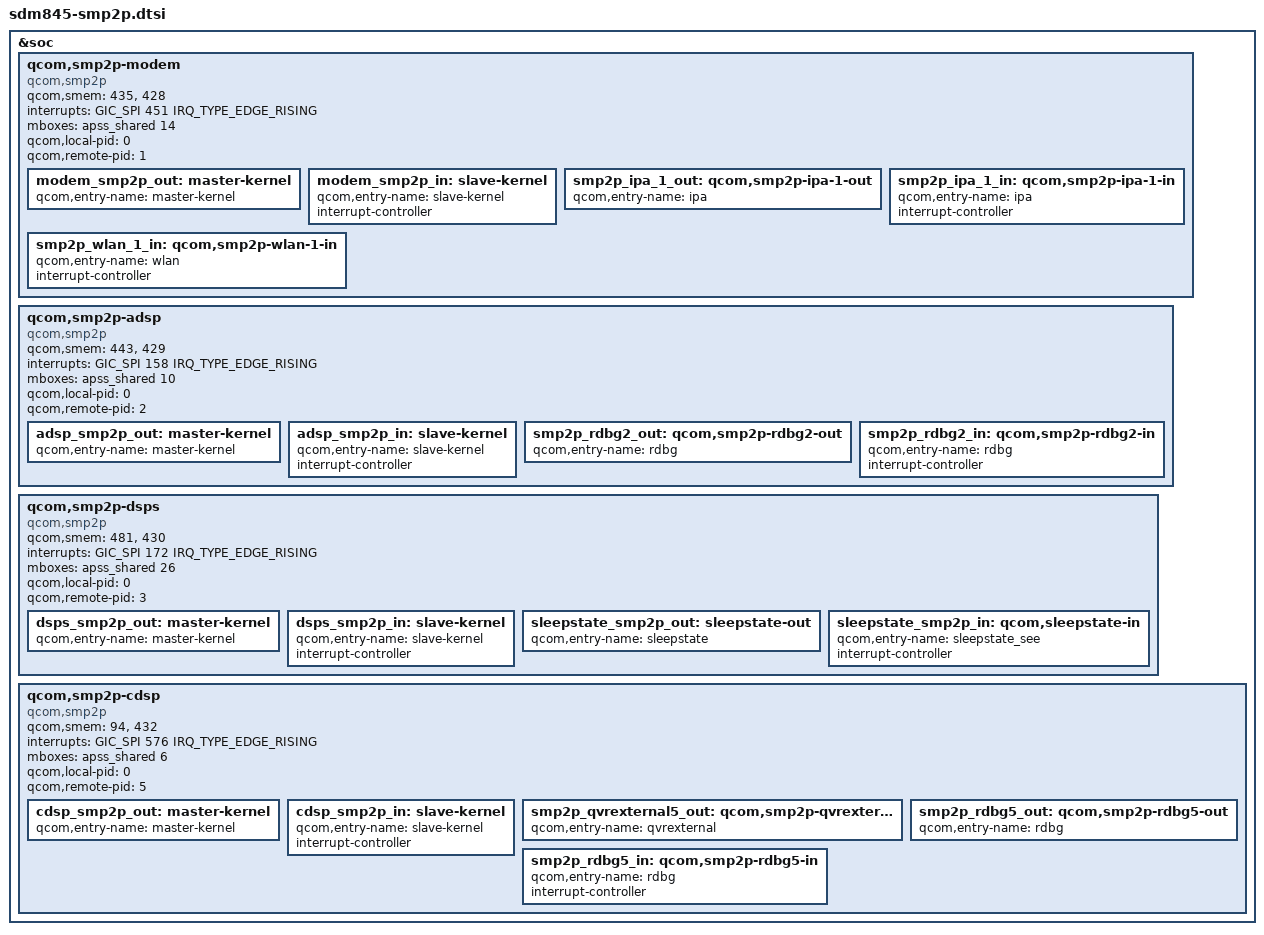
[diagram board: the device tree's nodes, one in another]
// SPDX-License-Identifier: GPL-2.0-only
/*
 * Copyright (c) 2016-2017, The Linux Foundation. All rights reserved.
 */

#include <dt-bindings/interrupt-controller/arm-gic.h>

&soc {
	qcom,smp2p-modem {
		compatible = "qcom,smp2p";
		qcom,smem = <435>, <428>;
		interrupts = <GIC_SPI 451 IRQ_TYPE_EDGE_RISING>;
		mboxes = <&apss_shared 14>;
		qcom,local-pid = <0>;
		qcom,remote-pid = <1>;

		modem_smp2p_out: master-kernel {
			qcom,entry-name = "master-kernel";
			#qcom,smem-state-cells = <1>;
		};

		modem_smp2p_in: slave-kernel {
			qcom,entry-name = "slave-kernel";
			interrupt-controller;
			#interrupt-cells = <2>;
		};

		smp2p_ipa_1_out: qcom,smp2p-ipa-1-out {
			qcom,entry-name = "ipa";
			#qcom,smem-state-cells = <1>;
		};

		/* ipa - inbound entry from mss */
		smp2p_ipa_1_in: qcom,smp2p-ipa-1-in {
			qcom,entry-name = "ipa";
			interrupt-controller;
			#interrupt-cells = <2>;
		};

		smp2p_wlan_1_in: qcom,smp2p-wlan-1-in {
			qcom,entry-name = "wlan";
			interrupt-controller;
			#interrupt-cells = <2>;
		};
	};

	qcom,smp2p-adsp {
		compatible = "qcom,smp2p";
		qcom,smem = <443>, <429>;
		interrupts = <GIC_SPI 158 IRQ_TYPE_EDGE_RISING>;
		mboxes = <&apss_shared 10>;
		qcom,local-pid = <0>;
		qcom,remote-pid = <2>;

		adsp_smp2p_out: master-kernel {
			qcom,entry-name = "master-kernel";
			#qcom,smem-state-cells = <1>;
		};

		adsp_smp2p_in: slave-kernel {
			qcom,entry-name = "slave-kernel";
			interrupt-controller;
			#interrupt-cells = <2>;
		};

		smp2p_rdbg2_out: qcom,smp2p-rdbg2-out {
			qcom,entry-name = "rdbg";
			#qcom,smem-state-cells = <1>;
		};

		smp2p_rdbg2_in: qcom,smp2p-rdbg2-in {
			qcom,entry-name = "rdbg";
			interrupt-controller;
			#interrupt-cells = <2>;
		};
	};

	qcom,smp2p-dsps {
		compatible = "qcom,smp2p";
		qcom,smem = <481>, <430>;
		interrupts = <GIC_SPI 172 IRQ_TYPE_EDGE_RISING>;
		mboxes = <&apss_shared 26>;
		qcom,local-pid = <0>;
		qcom,remote-pid = <3>;

		dsps_smp2p_out: master-kernel {
			#address-cells = <0>;
			qcom,entry-name = "master-kernel";
			#qcom,smem-state-cells = <1>;
		};

		dsps_smp2p_in: slave-kernel {
			#address-cells = <0>;
			qcom,entry-name = "slave-kernel";
			interrupt-controller;
			#interrupt-cells = <2>;
		};

		sleepstate_smp2p_out: sleepstate-out {
			#address-cells = <0>;
			qcom,entry-name = "sleepstate";
			#qcom,smem-state-cells = <1>;
		};

		sleepstate_smp2p_in: qcom,sleepstate-in {
			#address-cells = <0>;
			qcom,entry-name = "sleepstate_see";
			interrupt-controller;
			#interrupt-cells = <2>;
		};
	};

	qcom,smp2p-cdsp {
		compatible = "qcom,smp2p";
		qcom,smem = <94>, <432>;
		interrupts = <GIC_SPI 576 IRQ_TYPE_EDGE_RISING>;
		mboxes = <&apss_shared 6>;
		qcom,local-pid = <0>;
		qcom,remote-pid = <5>;

		cdsp_smp2p_out: master-kernel {
			#address-cells = <0>;
			qcom,entry-name = "master-kernel";
			#qcom,smem-state-cells = <1>;
		};

		cdsp_smp2p_in: slave-kernel {
			#address-cells = <0>;
			qcom,entry-name = "slave-kernel";
			interrupt-controller;
			#interrupt-cells = <2>;
		};

		smp2p_qvrexternal5_out: qcom,smp2p-qvrexternal5-out {
			#address-cells = <0>;
			qcom,entry-name = "qvrexternal";
			#qcom,smem-state-cells = <1>;
		};

		smp2p_rdbg5_out: qcom,smp2p-rdbg5-out {
			#address-cells = <0>;
			qcom,entry-name = "rdbg";
			#qcom,smem-state-cells = <1>;
		};

		smp2p_rdbg5_in: qcom,smp2p-rdbg5-in {
			#address-cells = <0>;
			qcom,entry-name = "rdbg";
			interrupt-controller;
			#interrupt-cells = <2>;
		};
	};
};
